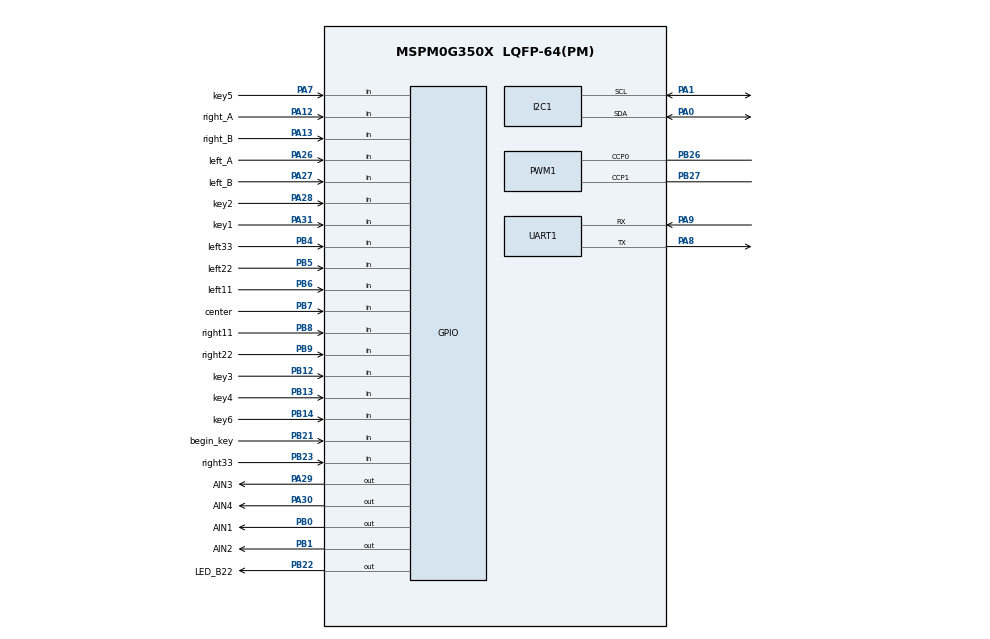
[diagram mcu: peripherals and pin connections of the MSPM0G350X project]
/**
 * @cliArgs --device "MSPM0G350X" --part "Default" --package "LQFP-64(PM)" --product "mspm0_sdk@2.10.00.04"
 * @versions {"tool":"1.26.2+4477"}
 */

/**
 * Import the modules used in this configuration.
 */
const GPIO    = scripting.addModule("/ti/driverlib/GPIO", {}, false);
const GPIO1   = GPIO.addInstance();
const GPIO2   = GPIO.addInstance();
const GPIO3   = GPIO.addInstance();
const GPIO4   = GPIO.addInstance();
const GPIO5   = GPIO.addInstance();
const I2C     = scripting.addModule("/ti/driverlib/I2C", {}, false);
const I2C1    = I2C.addInstance();
const PWM     = scripting.addModule("/ti/driverlib/PWM", {}, false);
const PWM1    = PWM.addInstance();
const SYSCTL  = scripting.addModule("/ti/driverlib/SYSCTL");
const SYSTICK = scripting.addModule("/ti/driverlib/SYSTICK");
const TIMER   = scripting.addModule("/ti/driverlib/TIMER", {}, false);
const TIMER1  = TIMER.addInstance();
const UART    = scripting.addModule("/ti/driverlib/UART", {}, false);
const UART1   = UART.addInstance();

/**
 * Write custom configuration values to the imported modules.
 */
const gate7  = system.clockTree["MFCLKGATE"];
gate7.enable = true;

GPIO1.$name                         = "LED";
GPIO1.associatedPins[0].$name       = "LED_B22";
GPIO1.associatedPins[0].pin.$assign = "PB22";

const Board = scripting.addModule("/ti/driverlib/Board", {}, false);

GPIO2.$name                              = "EECODER";
GPIO2.associatedPins.create(4);
GPIO2.associatedPins[0].$name            = "left_A";
GPIO2.associatedPins[0].direction        = "INPUT";
GPIO2.associatedPins[0].internalResistor = "PULL_DOWN";
GPIO2.associatedPins[0].interruptEn      = true;
GPIO2.associatedPins[0].polarity         = "RISE_FALL";
GPIO2.associatedPins[0].pin.$assign      = "PA26";
GPIO2.associatedPins[1].$name            = "left_B";
GPIO2.associatedPins[1].direction        = "INPUT";
GPIO2.associatedPins[1].internalResistor = "PULL_UP";
GPIO2.associatedPins[1].pin.$assign      = "PA27";
GPIO2.associatedPins[2].$name            = "right_A";
GPIO2.associatedPins[2].direction        = "INPUT";
GPIO2.associatedPins[2].interruptEn      = true;
GPIO2.associatedPins[2].internalResistor = "PULL_DOWN";
GPIO2.associatedPins[2].polarity         = "RISE_FALL";
GPIO2.associatedPins[2].pin.$assign      = "PA12";
GPIO2.associatedPins[3].$name            = "right_B";
GPIO2.associatedPins[3].direction        = "INPUT";
GPIO2.associatedPins[3].internalResistor = "PULL_UP";
GPIO2.associatedPins[3].pin.$assign      = "PA13";

GPIO3.$name                         = "MOTOR";
GPIO3.associatedPins.create(4);
GPIO3.associatedPins[0].$name       = "AIN1";
GPIO3.associatedPins[0].pin.$assign = "PB0";
GPIO3.associatedPins[1].$name       = "AIN2";
GPIO3.associatedPins[1].pin.$assign = "PB1";
GPIO3.associatedPins[2].$name       = "AIN3";
GPIO3.associatedPins[2].pin.$assign = "PA29";
GPIO3.associatedPins[3].$name       = "AIN4";
GPIO3.associatedPins[3].pin.$assign = "PA30";

GPIO4.$name                         = "road";
GPIO4.associatedPins.create(7);
GPIO4.associatedPins[0].$name       = "left33";
GPIO4.associatedPins[0].direction   = "INPUT";
GPIO4.associatedPins[0].pin.$assign = "PB4";
GPIO4.associatedPins[1].$name       = "left22";
GPIO4.associatedPins[1].direction   = "INPUT";
GPIO4.associatedPins[1].pin.$assign = "PB5";
GPIO4.associatedPins[2].$name       = "left11";
GPIO4.associatedPins[2].direction   = "INPUT";
GPIO4.associatedPins[2].pin.$assign = "PB6";
GPIO4.associatedPins[3].$name       = "center";
GPIO4.associatedPins[3].direction   = "INPUT";
GPIO4.associatedPins[3].pin.$assign = "PB7";
GPIO4.associatedPins[4].$name       = "right11";
GPIO4.associatedPins[4].direction   = "INPUT";
GPIO4.associatedPins[4].pin.$assign = "PB8";
GPIO4.associatedPins[5].direction   = "INPUT";
GPIO4.associatedPins[5].$name       = "right22";
GPIO4.associatedPins[5].pin.$assign = "PB9";
GPIO4.associatedPins[6].$name       = "right33";
GPIO4.associatedPins[6].direction   = "INPUT";
GPIO4.associatedPins[6].pin.$assign = "PB23";

GPIO5.$name                              = "key";
GPIO5.associatedPins.create(7);
GPIO5.associatedPins[0].$name            = "key1";
GPIO5.associatedPins[0].direction        = "INPUT";
GPIO5.associatedPins[0].internalResistor = "PULL_UP";
GPIO5.associatedPins[0].pin.$assign      = "PA31";
GPIO5.associatedPins[1].$name            = "key2";
GPIO5.associatedPins[1].direction        = "INPUT";
GPIO5.associatedPins[1].internalResistor = "PULL_UP";
GPIO5.associatedPins[1].pin.$assign      = "PA28";
GPIO5.associatedPins[2].$name            = "key3";
GPIO5.associatedPins[2].direction        = "INPUT";
GPIO5.associatedPins[2].internalResistor = "PULL_UP";
GPIO5.associatedPins[2].pin.$assign      = "PB12";
GPIO5.associatedPins[3].$name            = "key4";
GPIO5.associatedPins[3].direction        = "INPUT";
GPIO5.associatedPins[3].internalResistor = "PULL_UP";
GPIO5.associatedPins[3].pin.$assign      = "PB13";
GPIO5.associatedPins[4].$name            = "key5";
GPIO5.associatedPins[4].direction        = "INPUT";
GPIO5.associatedPins[4].internalResistor = "PULL_UP";
GPIO5.associatedPins[4].pin.$assign      = "PA7";
GPIO5.associatedPins[5].$name            = "key6";
GPIO5.associatedPins[5].direction        = "INPUT";
GPIO5.associatedPins[5].internalResistor = "PULL_UP";
GPIO5.associatedPins[5].pin.$assign      = "PB14";
GPIO5.associatedPins[6].$name            = "begin_key";
GPIO5.associatedPins[6].direction        = "INPUT";
GPIO5.associatedPins[6].internalResistor = "PULL_UP";
GPIO5.associatedPins[6].pin.$assign      = "PB21";

I2C1.$name                             = "OLED";
I2C1.basicEnableController             = true;
I2C1.advDigitalGlitchFilter            = "CLOCKS_1";
I2C1.advControllerRXFIFOTRIG           = "BYTES_8";
I2C1.advControllerTXFIFOTRIG           = "BYTES_7";
I2C1.enableDMAEvent1                   = false;
I2C1.enableDMAEvent2                   = false;
I2C1.peripheral.$assign                = "I2C0";
I2C1.peripheral.sdaPin.$assign         = "PA0";
I2C1.peripheral.sclPin.$assign         = "PA1";
I2C1.sdaPinConfig.hideOutputInversion  = scripting.forceWrite(false);
I2C1.sdaPinConfig.onlyInternalResistor = scripting.forceWrite(false);
I2C1.sdaPinConfig.passedPeripheralType = scripting.forceWrite("Digital");
I2C1.sdaPinConfig.$name                = "ti_driverlib_gpio_GPIOPinGeneric2";
I2C1.sdaPinConfig.enableConfig         = true;
I2C1.sclPinConfig.hideOutputInversion  = scripting.forceWrite(false);
I2C1.sclPinConfig.onlyInternalResistor = scripting.forceWrite(false);
I2C1.sclPinConfig.passedPeripheralType = scripting.forceWrite("Digital");
I2C1.sclPinConfig.$name                = "ti_driverlib_gpio_GPIOPinGeneric3";
I2C1.sclPinConfig.enableConfig         = true;

PWM1.$name                      = "PWM_0";
PWM1.timerStartTimer            = true;
PWM1.timerCount                 = 3000;
PWM1.clockDivider               = 2;
PWM1.peripheral.$assign         = "TIMA1";
PWM1.peripheral.ccp0Pin.$assign = "PB26";
PWM1.peripheral.ccp1Pin.$assign = "PB27";
PWM1.PWM_CHANNEL_0.$name        = "ti_driverlib_pwm_PWMTimerCC0";
PWM1.PWM_CHANNEL_0.invert       = true;
PWM1.PWM_CHANNEL_1.$name        = "ti_driverlib_pwm_PWMTimerCC1";
PWM1.PWM_CHANNEL_1.invert       = true;
PWM1.ccp0PinConfig.$name        = "ti_driverlib_gpio_GPIOPinGeneric0";
PWM1.ccp1PinConfig.$name        = "ti_driverlib_gpio_GPIOPinGeneric1";

SYSCTL.forceDefaultClkConfig = true;
SYSCTL.clockTreeEn           = true;

TIMER1.$name            = "TIMER_0";
TIMER1.timerStartTimer  = true;
TIMER1.timerClkDiv      = 8;
TIMER1.interrupts       = ["ZERO"];
TIMER1.timerMode        = "PERIODIC";
TIMER1.timerClkPrescale = 100;
TIMER1.timerPeriod      = "10ms";

UART1.$name                            = "UART1";
UART1.uartClkSrc                       = "MFCLK";
UART1.enabledInterrupts                = ["RX"];
UART1.peripheral.$assign               = "UART1";
UART1.peripheral.rxPin.$assign         = "PA9";
UART1.peripheral.txPin.$assign         = "PA8";
UART1.txPinConfig.$name                = "ti_driverlib_gpio_GPIOPinGeneric4";
UART1.txPinConfig.direction            = scripting.forceWrite("OUTPUT");
UART1.txPinConfig.hideOutputInversion  = scripting.forceWrite(false);
UART1.txPinConfig.onlyInternalResistor = scripting.forceWrite(false);
UART1.txPinConfig.passedPeripheralType = scripting.forceWrite("Digital");
UART1.rxPinConfig.$name                = "ti_driverlib_gpio_GPIOPinGeneric5";
UART1.rxPinConfig.hideOutputInversion  = scripting.forceWrite(false);
UART1.rxPinConfig.onlyInternalResistor = scripting.forceWrite(false);
UART1.rxPinConfig.passedPeripheralType = scripting.forceWrite("Digital");

/**
 * Pinmux solution for unlocked pins/peripherals. This ensures that minor changes to the automatic solver in a future
 * version of the tool will not impact the pinmux you originally saw.  These lines can be completely deleted in order to
 * re-solve from scratch.
 */
Board.peripheral.$suggestSolution          = "DEBUGSS";
Board.peripheral.swclkPin.$suggestSolution = "PA20";
Board.peripheral.swdioPin.$suggestSolution = "PA19";
TIMER1.peripheral.$suggestSolution         = "TIMA0";
